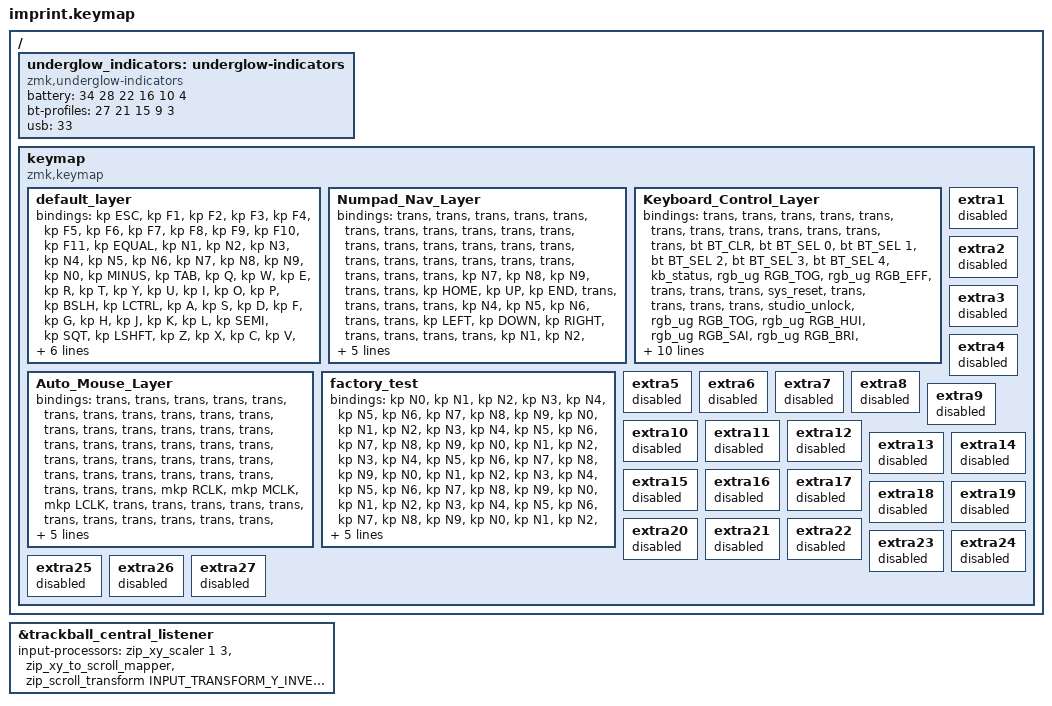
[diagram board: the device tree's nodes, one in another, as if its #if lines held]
#include <input/processors.dtsi>
#include <dt-bindings/zmk/input_transform.h>
#include <behaviors.dtsi>
#include <dt-bindings/zmk/bt.h>
#include <dt-bindings/zmk/keys.h>
#include <dt-bindings/zmk/pointing.h>
#include <dt-bindings/zmk/rgb.h>

/ {
    // Keyboard Status display (&kb_status, Keyboard_Control_Layer). Each half
    // reads this node and draws on its own LEDs: both halves show their own
    // battery on the row below the number row, and the left (central) half also
    // shows BLE profiles 1-5 on the number-row 1-5 keys and USB on the = key.
    // Indices are WS2812 chain positions for the standard layout (41 LEDs per
    // half, mirrored on the right), listed pinky -> centre.
    underglow_indicators: underglow-indicators {
        compatible = "zmk,underglow-indicators";
        battery = < 34 28 22 16 10 4 >;
        bt-profiles = < 27 21 15 9 3 >;
        usb = < 33 >;
    };

    keymap {
        compatible = "zmk,keymap";

        default_layer {
            bindings = <
&kp ESC    &kp F1  &kp F2    &kp F3    &kp F4    &kp F5              &kp F6     &kp F7    &kp F8     &kp F9    &kp F10   &kp F11
&kp EQUAL  &kp N1  &kp N2    &kp N3    &kp N4    &kp N5              &kp N6     &kp N7    &kp N8     &kp N9    &kp N0    &kp MINUS
&kp TAB    &kp Q   &kp W     &kp E     &kp R     &kp T               &kp Y      &kp U     &kp I      &kp O     &kp P     &kp BSLH
&kp LCTRL  &kp A   &kp S     &kp D     &kp F     &kp G               &kp H      &kp J     &kp K      &kp L     &kp SEMI  &kp SQT
&kp LSHFT  &kp Z   &kp X     &kp C     &kp V     &kp B               &kp N      &kp M     &kp COMMA  &kp DOT   &kp FSLH  &kp RSHFT
&trans     &trans  &kp LGUI  &kp LALT  &trans                                   &trans    &kp LBKT   &kp RBKT  &trans    &trans
                                       &kp RET   &kp DEL  &kp ESC    &kp GRAVE  &kp BSPC  &kp SPACE
                                       &kp LGUI  &mo 1    &mo 2      &kp CAPS   &mo 2     &mo 1
            >;
        };

        Numpad_Nav_Layer {
            bindings = <
&trans  &trans  &trans  &trans  &trans  &trans            &trans  &trans    &trans    &trans     &trans  &trans
&trans  &trans  &trans  &trans  &trans  &trans            &trans  &trans    &trans    &trans     &trans  &trans
&trans  &trans  &kp N7  &kp N8  &kp N9  &trans            &trans  &kp HOME  &kp UP    &kp END    &trans  &trans
&trans  &trans  &kp N4  &kp N5  &kp N6  &trans            &trans  &kp LEFT  &kp DOWN  &kp RIGHT  &trans  &trans
&trans  &trans  &kp N1  &kp N2  &kp N3  &trans            &trans  &trans    &trans    &trans     &trans  &trans
&trans  &trans  &trans  &kp N0  &trans                            &trans    &trans    &trans     &trans  &trans
                                &trans  &trans  &trans    &trans  &trans    &trans
                                &trans  &trans  &trans    &trans  &trans    &trans
            >;
        };

        Keyboard_Control_Layer {
            bindings = <
&trans       &trans        &trans        &trans        &trans        &trans                  &trans  &trans           &trans           &trans           &trans           &trans
&bt BT_CLR   &bt BT_SEL 0  &bt BT_SEL 1  &bt BT_SEL 2  &bt BT_SEL 3  &bt BT_SEL 4
#ifdef RGB_STATUS
    &kb_status          /* battery + output status on the underglow for a few seconds */
#else
    &trans              /* &kb_status is a Cyboard ZMK extension (zmk-private) */
#endif
                                                                                    &rgb_ug RGB_TOG  &rgb_ug RGB_EFF  &trans           &trans           &trans
&sys_reset   &trans        &trans        &trans        &trans        &studio_unlock          &rgb_ug RGB_TOG  &rgb_ug RGB_HUI  &rgb_ug RGB_SAI  &rgb_ug RGB_BRI  &rgb_ug RGB_SPI  &sys_reset
&bootloader  &trans        &trans        &trans        &trans        &trans                  &trans  &rgb_ug RGB_HUD  &rgb_ug RGB_SAD  &rgb_ug RGB_BRD  &rgb_ug RGB_SPD  &bootloader
&to 4        &trans        &trans        &trans        &trans        &trans                  &trans  &trans           &trans           &trans           &trans           &to 4
&to 4        &trans        &trans        &trans        &trans                                        &trans           &trans           &trans           &trans           &to 4
                                                       &trans        &trans        &trans    &trans  &trans           &trans
                                                       &trans        &trans        &trans    &trans  &trans           &trans
            >;
        };

        Auto_Mouse_Layer {
            bindings = <
&trans  &trans  &trans     &trans     &trans     &trans            &trans  &trans  &trans  &trans  &trans  &trans
&trans  &trans  &trans     &trans     &trans     &trans            &trans  &trans  &trans  &trans  &trans  &trans
&trans  &trans  &trans     &trans     &trans     &trans            &trans  &trans  &trans  &trans  &trans  &trans
&trans  &trans  &mkp RCLK  &mkp MCLK  &mkp LCLK  &trans            &trans  &trans  &trans  &trans  &trans  &trans
&trans  &trans  &trans     &trans     &trans     &trans            &trans  &trans  &trans  &trans  &trans  &trans
&trans  &trans  &trans     &trans     &trans                               &trans  &trans  &trans  &trans  &trans
                                      &trans     &trans  &trans    &trans  &trans  &trans
                                      &trans     &trans  &trans    &trans  &trans  &trans
            >;
        };

        factory_test {
            bindings = <
&kp N0  &kp N1  &kp N2  &kp N3  &kp N4  &kp N5            &kp N6  &kp N7  &kp N8  &kp N9  &kp N0  &kp N1
&kp N2  &kp N3  &kp N4  &kp N5  &kp N6  &kp N7            &kp N8  &kp N9  &kp N0  &kp N1  &kp N2  &kp N3
&kp N4  &kp N5  &kp N6  &kp N7  &kp N8  &kp N9            &kp N0  &kp N1  &kp N2  &kp N3  &kp N4  &kp N5
&kp N6  &kp N7  &kp N8  &kp N9  &kp N0  &kp N1            &kp N2  &kp N3  &kp N4  &kp N5  &kp N6  &kp N7
&kp N8  &kp N9  &kp N0  &kp N1  &kp N2  &kp N3            &kp N4  &kp N5  &kp N6  &kp N7  &kp N8  &kp N9
&kp N0  &kp N1  &kp N2  &kp N3  &kp N4                            &kp N6  &kp N7  &kp N8  &kp N9  &kp N0
                                &kp N1  &kp N2  &kp N3    &kp N4  &kp N5  &kp N6
                                &kp N7  &kp N8  &kp N9    &kp N0  &kp N1  &kp N2
            >;
        };

        // Reserved empty layers: skipped in regular builds, but compiled into
        // ZMK Studio builds so users can add layers at runtime ("Add Layer"
        // only works for layers that exist in the firmware). ZMK tracks layer
        // state in a 32-bit mask, so 5 active + 27 reserved = 32 is the
        // maximum. Keep these AFTER all active layers: the initial layer
        // ordering assumes the active layers are the first keymap children.
        extra1 {
            status = "reserved";
        };

        extra2 {
            status = "reserved";
        };

        extra3 {
            status = "reserved";
        };

        extra4 {
            status = "reserved";
        };

        extra5 {
            status = "reserved";
        };

        extra6 {
            status = "reserved";
        };

        extra7 {
            status = "reserved";
        };

        extra8 {
            status = "reserved";
        };

        extra9 {
            status = "reserved";
        };

        extra10 {
            status = "reserved";
        };

        extra11 {
            status = "reserved";
        };

        extra12 {
            status = "reserved";
        };

        extra13 {
            status = "reserved";
        };

        extra14 {
            status = "reserved";
        };

        extra15 {
            status = "reserved";
        };

        extra16 {
            status = "reserved";
        };

        extra17 {
            status = "reserved";
        };

        extra18 {
            status = "reserved";
        };

        extra19 {
            status = "reserved";
        };

        extra20 {
            status = "reserved";
        };

        extra21 {
            status = "reserved";
        };

        extra22 {
            status = "reserved";
        };

        extra23 {
            status = "reserved";
        };

        extra24 {
            status = "reserved";
        };

        extra25 {
            status = "reserved";
        };

        extra26 {
            status = "reserved";
        };

        extra27 {
            status = "reserved";
        };
    };
};

// right hand trackball configuration

// &trackball_peripheral_listener {
//    input-processors =
//     activate layer 3 within 500ms of the trackball moving
//     <&zip_temp_layer 3 500>;
// };

//left hand trackball configuration

&trackball_central_listener {
    input-processors =
        // multiply sensitivity by 1, divide by 3 (make it slower for scrolling),
        <&zip_xy_scaler 1 3>,
        // make this trackball output scrolling events by default instead of cursor movement,
        <&zip_xy_to_scroll_mapper>,
        // invert vertical scrolling so that the view moves in the same direction as the top of the trackball.,
        <&zip_scroll_transform INPUT_TRANSFORM_Y_INVERT>;
};
